# rCSL_pll_001 register map
Vendor: Texas Instruments
Peripheral module from a debugger description file (folder OMAPL138_C6748).
Registers are 32-bit, access not given, reset 0x0 unless marked. A register's access mark holds for its fields unless they carry their own. Offsets are as the file gives them; lines under a group give offsets from that group; [hi:lo] are bit positions; {n}, {i} and the like mark numbered series; 'fields as' and 'values as' point back to an identical list; <NAME> marks a mode.

## PLLC — This module propagates reset and clocks to the device
0x00 REVID ro reset 0x44813C00 — Contains peripheral ID and revision information
  [31:0] REV — Revision Identification Number
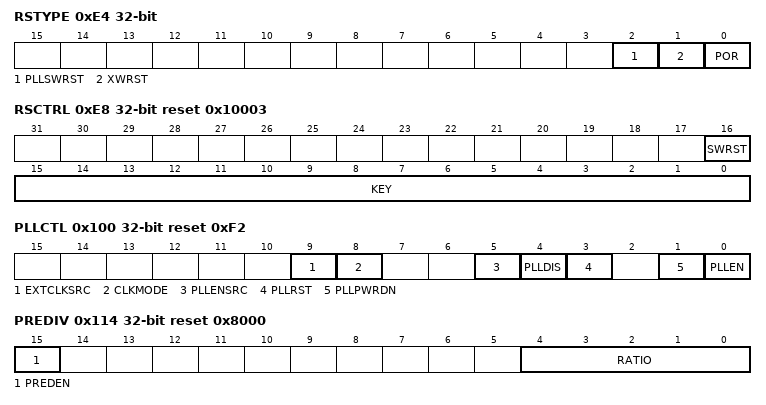
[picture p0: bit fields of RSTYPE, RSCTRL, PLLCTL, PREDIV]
0xE4 RSTYPE — Latches cause of the last reset. Although the reset value of all bits are 0, after coming out of reset, one bit will be set to one to indicate cause of reset. Some bits may not be doc'd to users.
  [all] fields
    0=NO; 1=YES
  [2] PLLSWRST ro — If 1, means that maximum reset was the reset to occur that is of highest priority
  [1] XWRST ro — If 1, means that external warm reset was the last reset to occur that is of highest priority
  [0] POR ro — If 1, means that power on reset was the last reset to occur that is of highest priority
0xE8 RSCTRL reset 0x10003 — Enables software-controlled device reset
  [16] SWRST rw — Software reset
    0=IN_RESET; 1=NOT_IN_RESET
  [15:0] KEY rw — Unlock Key
    3=LOCKED; 12=UNLOCKED; 0x5A69=UNLOCK_KEY
0x100 PLLCTL reset 0xF2 — Controls PLL operations.
  [9] EXTCLKSRC rw — Enable external clock source for PLL bypass mode
    0=DISABLE; 1=ENABLE
  [8] CLKMODE rw — Reference Clock Selection; Actual default determined by module tieoff. May lock default value and doc as Reserved to users
    0=OSCIN (Internal oscillator); 1=CLKIN (CLKIN square wave)
  [5] PLLENSRC rw — PLLEN mux control source. Actual default determined by module tieoff. May lock default value and doc as Reserved to users
    0=CLEAR
  [4] PLLDIS rw — Asserts DISABLE to PLL if supported. Actual default determined by module tieoff.
    0=DEASSERT (PLL disable de-asserted); 1=ASSERT (PLL disable asserted)
  [3] PLLRST rw — Asserts RESET to PLL if supported. Actual default determined by module tieoff.
    0=ASSERT; 1=DEASSERT
  [1] PLLPWRDN rw — PLL Power down. Actual default determined by module tieoff
    0=POWERED_UP (PLL operation); 1=POWERED_DOWN (PLL power down)
  [0] PLLEN rw — PLL Mode Enable
    0=BYPASS (Bypass mode); 1=PLL (PLL mode, not bypassed)
0x104 OCSEL (reset mask 0xFFFFFFE0) — OBSCLK Select Register
  [4:0] OCSRC rw — OBSCLK source
0x110 PLLM reset 0x10 — PLL Multiplier Control Register
  [4:0] PLLM rw — PLL Multiplier Select. Actual default determined by module tieoff.
0x114 PREDIV reset 0x8000 — Pre-Divider control.
  [15] PREDEN rw — Pre_Divider enable. Actual default determined by module tieoff
    0=DISABLE; 1=ENABLE
  [4:0] RATIO rw — Divider ratio. Actual default determined by module tieoff. May lock default and make bit R only
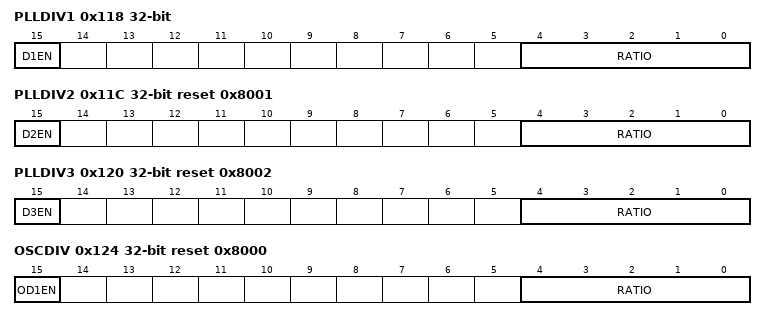
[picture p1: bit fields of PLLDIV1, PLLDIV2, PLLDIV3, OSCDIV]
0x118 PLLDIV1 — Divider 1 control--divider for SYSCLK1.
  [15] D1EN rw — Divider Enable. Actual default determined by module tieoff. May lock default and make bit R only
    0=DISABLE; 1=ENABLE
  [4:0] RATIO rw — Divider ratio. Actual default determined by module tieoff. May lock default and make bit R only
0x11C PLLDIV2 reset 0x8001 — Divider 2 control--divider for SYSCLK2.
  [15] D2EN rw — Divider Enable. Actual default determined by module tieoff. May lock default and make bit R only
    0=DISABLE; 1=ENABLE
  [4:0] RATIO rw — Divider ratio. Actual default determined by module tieoff. May lock default and make bit R only
0x120 PLLDIV3 reset 0x8002 — Divider 3 control--divider for SYSCLK3.
  [15] D3EN rw — Divider Enable. Actual default determined by module tieoff. May lock default and make bit R only
    0=DISABLE; 1=ENABLE
  [4:0] RATIO rw — Divider ratio. Actual default determined by module tieoff. May lock default and make bit R only
0x124 OSCDIV reset 0x8000 — Oscillator Divider
  [15] OD1EN rw — Divider Enable. Actual default determined by module tieoff. May lock default and make bit R only
    0=DISABLE; 1=ENABLE
  [4:0] RATIO rw — Divider ratio. Actual default determined by module tieoff. May lock default and make bit R only
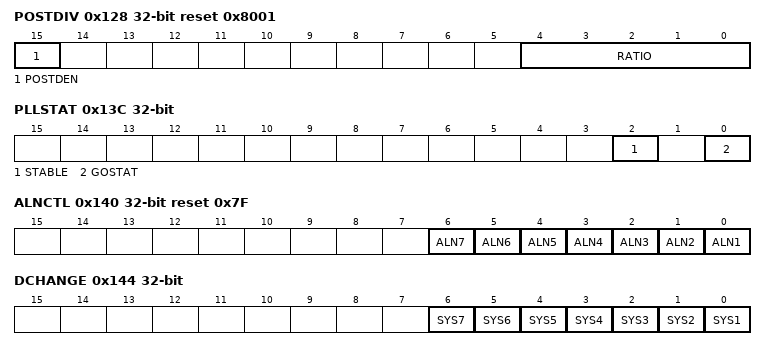
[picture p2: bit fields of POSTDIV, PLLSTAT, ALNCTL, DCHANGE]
0x128 POSTDIV reset 0x8001 — Post-Divider control.
  [15] POSTDEN rw — Post_Divider enable. Actual default determined by module tieoff
    0=DISABLE; 1=ENABLE
  [4:0] RATIO rw — Divider ratio. Actual default determined by module tieoff. May lock default and make bit R only
0x138 PLLCMD — contains command bits for various operations. Writes of 1 initiates command. Writes of 0 clear the bit but have no effect.
  [0] GOSET rw — GO bit for SYSCLKx phase alignment
    0=CLRBIT (Clear bit (no effect)); 1=PHASE_ALIGN (Phase alignment)
0x13C PLLSTAT — shows PLLCTRL status.
  [2] STABLE ro — OSC counter done, oscillator assumed to be stable. By the time device comes out of reset, this bit should become 1. May not need to document
    0=OSC_NOT_STABLE; 1=OSC_STABLE
  [0] GOSTAT ro — Status of GO operation. If 1, indicates GO operation in progress.
    0=NONE; 1=INPROG
0x140 ALNCTL reset 0x7F — Indicates which SYSCLKs need to be aligned for proper device operation. May lock defaults and make register R only. Actual default determined by module tieoff.
  [all] fields
    0=NO; 1=YES
  [n-1] ALN{n} rw (n=1..7) — SYSCLK{n} needs to be aligned to others selected in this register
0x144 DCHANGE — Indicates if SYSCLK divide ratio has been modified.
  [all] fields
    0=NO (ratio not modified); 1=YES (ratio modified)
  [n-1] SYS{n} ro (n=1..7) — SYSCLK{n} divide ratio is modified
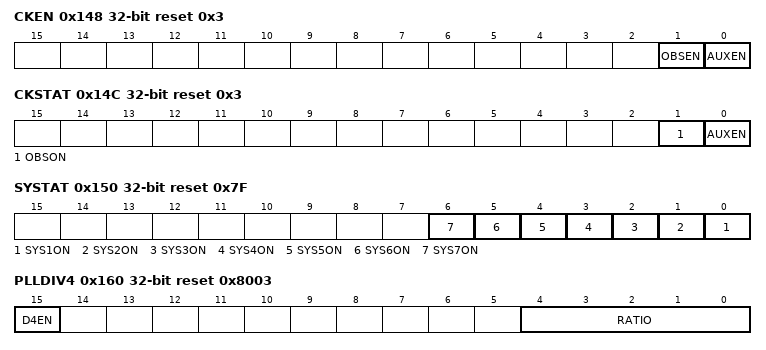
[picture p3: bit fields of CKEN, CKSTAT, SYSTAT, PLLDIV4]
0x148 CKEN reset 0x3 — clock enable control for miscellaneous output clocks.
  [1] OBSEN rw — OBSCLK enable.
    0=DISABLE; 1=ENABLE
  [0] AUXEN rw — AUXCLK enable. Actual default determined by tieoff. Only document if clk exists
    0=DISABLE; 1=ENABLE
0x14C CKSTAT reset 0x3 — Clock status for all clocks except SYSCLKx.
  [1] OBSON ro — OBSCLK on status.
    0=OFF; 1=ON
  [0] AUXEN ro — AUXCLK on status. Actual default determined by tieoff.
    0=OFF; 1=ON
0x150 SYSTAT reset 0x7F — Indicates SYSCLK on/off status. Only document necessary bits to customers. Actual default determined by actual clock on/off status, which depends on PLLDIV[n].D[n]EN bit default
  [all] fields
    0=OFF; 1=ON
  [n-1] SYS{n}ON ro (n=1..7) — SYSCLK{n} on status
0x160 PLLDIV4 reset 0x8003 — Divider 4 control--divider for SYSCLK4,
  [15] D4EN rw — Divider Enable. Actual default determined by module tieoff. May lock default and make bit R only
    0=DISABLE; 1=ENABLE
  [4:0] RATIO rw — Divider ratio. Actual default determined by module tieoff. May lock default and make bit R only
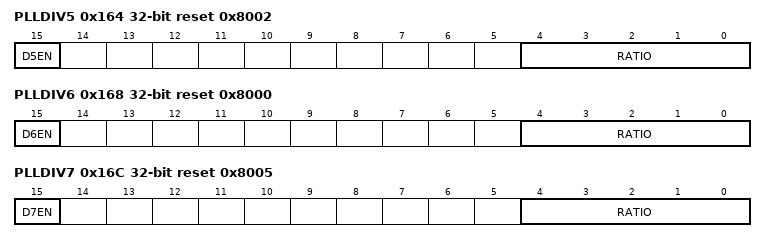
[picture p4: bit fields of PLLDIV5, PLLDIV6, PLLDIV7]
0x164 PLLDIV5 reset 0x8002 — Divider 5 control--divider for SYSCLK5.
  [15] D5EN rw — Divider Enable. Actual default determined by module tieoff. May lock default and make bit R only
    0=DISABLE; 1=ENABLE
  [4:0] RATIO rw — Divider ratio. Actual default determined by module tieoff. May lock default and make bit R only
0x168 PLLDIV6 reset 0x8000 — Divider 6 control--divider for SYSCLK6.
  [15] D6EN rw — Divider Enable. Actual default determined by module tieoff. May lock default and make bit R only
    0=DISABLE; 1=ENABLE
  [4:0] RATIO rw — Divider ratio. Actual default determined by module tieoff. May lock default and make bit R only
0x16C PLLDIV7 reset 0x8005 — Divider 7 control--divider for SYSCLK7.
  [15] D7EN rw — Divider Enable. Actual default determined by module tieoff. May lock default and make bit R only
    0=DISABLE; 1=ENABLE
  [4:0] RATIO rw — Divider ratio. Actual default determined by module tieoff. May lock default and make bit R only
0x1F0 EMUCNT0 ro — Emulation Performance Counter 0 Register
  [31:0] COUNT — Counter value for lower 64 bits
0x1F4 EMUCNT1 ro — Emulation Performance Counter 1 Register
  [31:0] COUNT — Counter value for upper 64 bits
